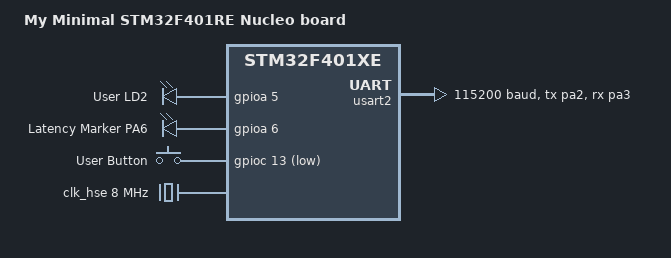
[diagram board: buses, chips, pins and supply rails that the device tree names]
/dts-v1/;

#include <st/f4/stm32f401Xe.dtsi>
#include <st/f4/stm32f401r(d-e)tx-pinctrl.dtsi>
#include <zephyr/dt-bindings/gpio/gpio.h>
#include <zephyr/dt-bindings/input/input-event-codes.h>

/ {
	model = "My Minimal STM32F401RE Nucleo board";
	compatible = "my,minimal-nucleo-f401re";

	chosen {
		zephyr,console = &usart2;
		zephyr,shell-uart = &usart2;
		zephyr,sram = &sram0;
		zephyr,flash = &flash0;
	};

	leds {
		compatible = "gpio-leds";

		user_led: led_0 {
			gpios = <&gpioa 5 GPIO_ACTIVE_HIGH>;
			label = "User LD2";
		};

		latency_marker: latency_marker {
        	gpios = <&gpioa 6 GPIO_ACTIVE_HIGH>;
        	label = "Latency Marker PA6";
    	};
	};

	gpio_keys {
		compatible = "gpio-keys";

		user_button: button_0 {
			gpios = <&gpioc 13 GPIO_ACTIVE_LOW>;
			label = "User Button";
			zephyr,code = <INPUT_KEY_0>;
		};
	};

	aliases {
		led0 = &user_led;
		sw0 = &user_button;
		latency0 = &latency_marker;
	};
};

&clk_hse {
	hse-bypass;
	clock-frequency = <DT_FREQ_M(8)>;
	status = "okay";
};

&pll {
	div-m = <8>;
	mul-n = <336>;
	div-p = <4>;
	div-q = <7>;
	clocks = <&clk_hse>;
	status = "okay";
};

&rcc {
	clocks = <&pll>;
	clock-frequency = <DT_FREQ_M(84)>;
	ahb-prescaler = <1>;
	apb1-prescaler = <2>;
	apb2-prescaler = <1>;
};

&usart2 {
	pinctrl-0 = <&usart2_tx_pa2 &usart2_rx_pa3>;
	pinctrl-names = "default";
	current-speed = <115200>;
	status = "okay";
};
